VERSION ""
NS_ :

BS_:

BU_: DCM FSM JSONCANTest

BO_ 200 DCM_vitals: 1 DCM
SG_ heartbeat : 0|1@1+ (1,0) [0|1] "" DEBUG

BO_ 201 DCM_canFifoOverflow: 8 DCM
SG_ txOverflowCount : 0|32@1+ (1,0) [0|4294967295] "" DEBUG
SG_ rxOverflowCount : 32|32@1+ (1,0) [0|4294967295] "" DEBUG

BO_ 203 DCM_watchdogTimeout: 4 DCM
SG_ taskName : 0|32@1+ (1,0) [0|4294967295] "" DEBUG

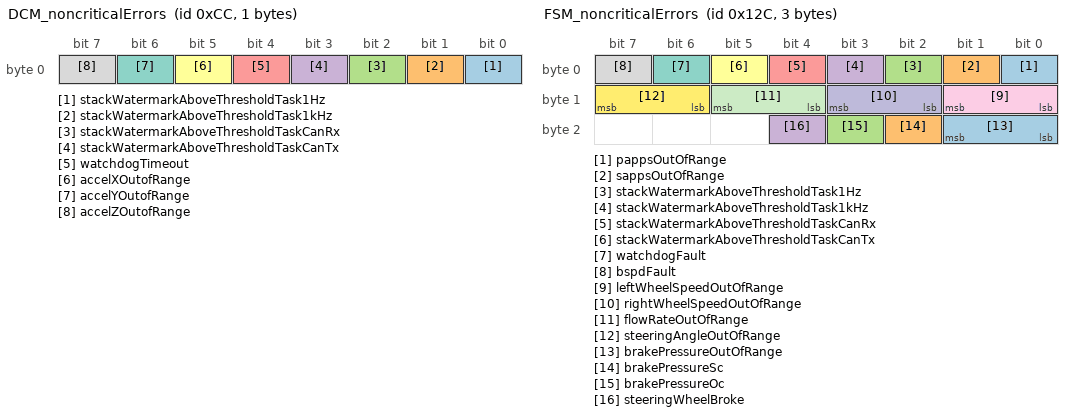
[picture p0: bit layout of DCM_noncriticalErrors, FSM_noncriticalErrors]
BO_ 204 DCM_noncriticalErrors: 1 DCM
SG_ stackWatermarkAboveThresholdTask1Hz : 0|1@1+ (1,0) [0|1] "" DEBUG
SG_ stackWatermarkAboveThresholdTask1kHz : 1|1@1+ (1,0) [0|1] "" DEBUG
SG_ stackWatermarkAboveThresholdTaskCanRx : 2|1@1+ (1,0) [0|1] "" DEBUG
SG_ stackWatermarkAboveThresholdTaskCanTx : 3|1@1+ (1,0) [0|1] "" DEBUG
SG_ watchdogTimeout : 4|1@1+ (1,0) [0|1] "" DEBUG
SG_ accelXOutofRange : 5|1@1+ (1,0) [0|1] "" DEBUG
SG_ accelYOutofRange : 6|1@1+ (1,0) [0|1] "" DEBUG
SG_ accelZOutofRange : 7|1@1+ (1,0) [0|1] "" DEBUG

BO_ 205 DCM_stateMachine: 1 DCM
SG_ state : 0|8@1+ (1,0) [0|255] "" DEBUG

BO_ 207 DCM_AIRShutdownErrors: 1 DCM
SG_ missingHeartbeat : 0|1@1+ (1,0) [0|1] "" DEBUG

BO_ 208 DCM_motorShutdownErrors: 1 DCM
SG_ missingHeartbeat : 0|1@1+ (1,0) [0|1] "" DEBUG

BO_ 212 DCM_inverterSwitches: 1 DCM
SG_ rightInverterSwitch : 0|1@1+ (1,0) [0|1] "" DEBUG
SG_ leftInverterSwitch : 1|1@1+ (1,0) [0|1] "" DEBUG

BO_ 13 FSM_pedalPosition: 4 FSM
SG_ mappedPedalPercentage : 0|32@1+ (2.3283064370807974e-08,0) [0|100] "%" DEBUG

BO_ 90 FSM_torqueLimiting: 4 FSM
SG_ FSM_torqueLimit : 0|32@1+ (3.492459655621196e-08,0) [0|150] "nM" DEBUG

BO_ 151 FSM_apps: 8 FSM
SG_ pappsMappedPedalPercentage : 0|32@1+ (2.3283064370807974e-08,0) [0|100] "%" DEBUG,JSONCANTest
SG_ sappsMappedPedalPercentage : 32|32@1+ (2.3283064370807974e-08,0) [0|100] "%" DEBUG,JSONCANTest

BO_ 300 FSM_noncriticalErrors: 3 FSM
SG_ pappsOutOfRange : 0|1@1+ (1,0) [0|1] "" DEBUG,JSONCANTest
SG_ sappsOutOfRange : 1|1@1+ (1,0) [0|1] "" DEBUG,JSONCANTest
SG_ stackWatermarkAboveThresholdTask1Hz : 2|1@1+ (1,0) [0|1] "" DEBUG,JSONCANTest
SG_ stackWatermarkAboveThresholdTask1kHz : 3|1@1+ (1,0) [0|1] "" DEBUG,JSONCANTest
SG_ stackWatermarkAboveThresholdTaskCanRx : 4|1@1+ (1,0) [0|1] "" DEBUG,JSONCANTest
SG_ stackWatermarkAboveThresholdTaskCanTx : 5|1@1+ (1,0) [0|1] "" DEBUG,JSONCANTest
SG_ watchdogFault : 6|1@1+ (1,0) [0|1] "" DEBUG,JSONCANTest
SG_ bspdFault : 7|1@1+ (1,0) [0|1] "" DEBUG,JSONCANTest
SG_ leftWheelSpeedOutOfRange : 8|2@1+ (1,0) [0|3] "" DEBUG,JSONCANTest
SG_ rightWheelSpeedOutOfRange : 10|2@1+ (1,0) [0|3] "" DEBUG,JSONCANTest
SG_ flowRateOutOfRange : 12|2@1+ (1,0) [0|3] "" DEBUG,JSONCANTest
SG_ steeringAngleOutOfRange : 14|2@1+ (1,0) [0|3] "" DEBUG,JSONCANTest
SG_ brakePressureOutOfRange : 16|2@1+ (1,0) [0|3] "" DEBUG,JSONCANTest
SG_ brakePressureSc : 18|1@1+ (1,0) [0|1] "" DEBUG,JSONCANTest
SG_ brakePressureOc : 19|1@1+ (1,0) [0|1] "" DEBUG,JSONCANTest
SG_ steeringWheelBroke : 20|1@1+ (1,0) [0|1] "" DEBUG,JSONCANTest

BO_ 301 FSM_vitals: 1 FSM
SG_ heartbeat : 0|1@1+ (1,0) [0|1] "" DEBUG

BO_ 302 FSM_canFifoOverflow: 8 FSM
SG_ txOverflowCount : 0|32@1+ (1,0) [0|4294967295] "" DEBUG
SG_ rxOverflowCount : 32|32@1+ (1,0) [0|4294967295] "" DEBUG

BO_ 304 FSM_watchdogTimeout: 1 FSM
SG_ taskName : 0|8@1+ (1,0) [0|255] "" DEBUG

BO_ 305 FSM_stateMachine: 1 FSM
SG_ state : 0|8@1+ (1,0) [0|255] "" DEBUG

BO_ 307 FSM_flowMeter: 1 FSM
SG_ flowRate : 0|8@1+ (0.39215686274509803,0) [0|100] "L/min" DEBUG

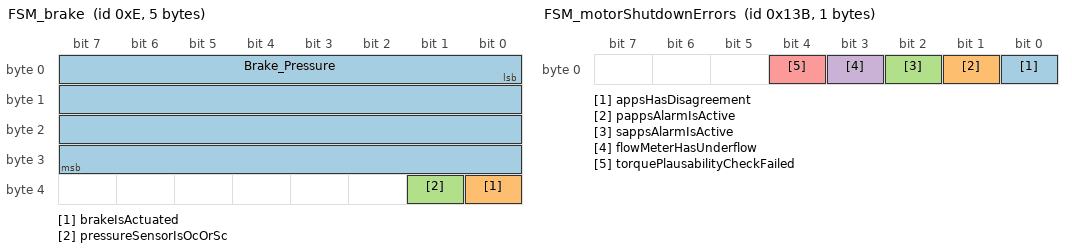
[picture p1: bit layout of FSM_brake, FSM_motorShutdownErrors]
BO_ 14 FSM_brake: 5 FSM
SG_ Brake_Pressure : 0|32@1+ (5.820766092701993e-07,0) [0|2500] "psi" DEBUG
SG_ brakeIsActuated : 32|1@1+ (1,0) [0|1] "" DEBUG
SG_ pressureSensorIsOcOrSc : 33|1@1+ (1,0) [0|1] "" DEBUG

BO_ 310 FSM_AIRShutdownErrors: 1 FSM
SG_ missingHeartbeat : 0|1@1+ (1,0) [0|1] "" DEBUG

BO_ 315 FSM_motorShutdownErrors: 1 FSM
SG_ appsHasDisagreement : 0|1@1+ (1,0) [0|1] "" DEBUG
SG_ pappsAlarmIsActive : 1|1@1+ (1,0) [0|1] "" DEBUG
SG_ sappsAlarmIsActive : 2|1@1+ (1,0) [0|1] "" DEBUG
SG_ flowMeterHasUnderflow : 3|1@1+ (1,0) [0|1] "" DEBUG
SG_ torquePlausabilityCheckFailed : 4|1@1+ (1,0) [0|1] "" DEBUG

BO_ 317 FSM_wheelSpeedSensors: 4 FSM
SG_ leftWheelSpeed : 0|16@1+ (0.0022888532845044634,0) [0|150] "km/h" DEBUG
SG_ rightWheelSpeed : 32|16@1+ (0.0022888532845044634,0) [0|150] "km/h" DEBUG

BO_ 318 FSM_steeringAngleSensor: 4 FSM
SG_ steeringAngle : 0|32@1+ (5.122274161577754e-08,-110) [-110|110] "km/h" DEBUG

BO_ 601 JSONCANTest_vitals: 5 JSONCANTest
SG_ heartbeat : 0|1@1+ (1.0,0) [0|1] "" DEBUG
SG_ timestamp : 1|32@1+ (1,0) [0|4294967295] "" DEBUG

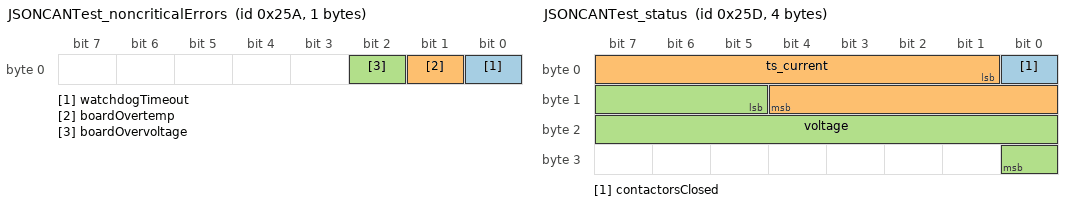
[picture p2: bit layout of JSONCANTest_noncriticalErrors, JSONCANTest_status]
BO_ 602 JSONCANTest_noncriticalErrors: 1 JSONCANTest
SG_ watchdogTimeout : 0|1@1+ (1,0) [0|1] "" DEBUG
SG_ boardOvertemp : 1|1@1+ (1,0) [0|1] "" DEBUG
SG_ boardOvervoltage : 2|1@1+ (1,0) [0|1] "" DEBUG

BO_ 603 JSONCANTest_AIRShutdownErrors: 1 JSONCANTest
SG_ dummyAirShutdown : 0|1@1+ (1,0) [0|1] "" DEBUG

BO_ 604 JSONCANTest_motorShutdownErrors: 1 JSONCANTest
SG_ dummyMotorShutdown : 0|1@1+ (1,0) [0|1] "" DEBUG

BO_ 605 JSONCANTest_status: 4 JSONCANTest
SG_ contactorsClosed : 0|1@1+ (1,0) [0|1] "" DEBUG
SG_ ts_current : 1|12@1+ (0.019536019536019536,0) [0|80] "A" DEBUG
SG_ voltage : 13|12@1+ (0.1221001221001221,0) [0|500] "V" DEBUG

BA_DEF_  "BusType" STRING ;
BA_DEF_ BO_  "GenMsgCycleTime" INT 20 7757;
BA_DEF_ SG_  "GenSigStartValue" INT 0 2147483647;

BA_DEF_DEF_  "BusType" "CAN";
BA_DEF_DEF_  "GenMsgCycleTime" 0;
BA_DEF_DEF_  "GenSigStartValue" 0;

BA_ "GenSigStartValue" SG_ 605 ts_current 50;

BA_ "GenMsgCycleTime" BO_ 200  1000;
BA_ "GenMsgCycleTime" BO_ 201  1000;
BA_ "GenMsgCycleTime" BO_ 203  1000;
BA_ "GenMsgCycleTime" BO_ 204  1000;
BA_ "GenMsgCycleTime" BO_ 205  1000;
BA_ "GenMsgCycleTime" BO_ 207  1000;
BA_ "GenMsgCycleTime" BO_ 208  1000;
BA_ "GenMsgCycleTime" BO_ 212  1000;
BA_ "GenMsgCycleTime" BO_ 13  1000;
BA_ "GenMsgCycleTime" BO_ 90  1000;
BA_ "GenMsgCycleTime" BO_ 151  1000;
BA_ "GenMsgCycleTime" BO_ 300  100;
BA_ "GenMsgCycleTime" BO_ 301  1000;
BA_ "GenMsgCycleTime" BO_ 302  1000;
BA_ "GenMsgCycleTime" BO_ 304  1000;
BA_ "GenMsgCycleTime" BO_ 305  1000;
BA_ "GenMsgCycleTime" BO_ 307  1000;
BA_ "GenMsgCycleTime" BO_ 14  1000;
BA_ "GenMsgCycleTime" BO_ 310  1000;
BA_ "GenMsgCycleTime" BO_ 315  1000;
BA_ "GenMsgCycleTime" BO_ 317  1000;
BA_ "GenMsgCycleTime" BO_ 318  1000;
BA_ "GenMsgCycleTime" BO_ 601  1000;
BA_ "GenMsgCycleTime" BO_ 602  None;
BA_ "GenMsgCycleTime" BO_ 603  1000;
BA_ "GenMsgCycleTime" BO_ 604  1000;
BA_ "GenMsgCycleTime" BO_ 605  1000;

VAL_ 200 heartbeat 0 "FALSE"1 "TRUE";
VAL_ 301 heartbeat 0 "FALSE"1 "TRUE";
VAL_ 605 contactorsClosed 0 "AIR_OPEN"1 "AIR_CLOSED";
